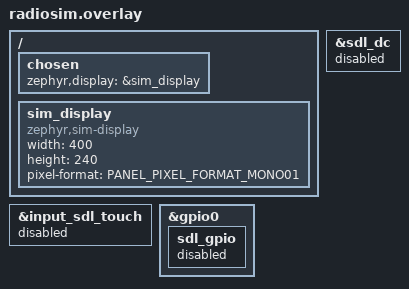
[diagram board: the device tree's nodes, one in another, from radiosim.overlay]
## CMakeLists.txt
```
# SPDX-License-Identifier: GPL-3.0-only

cmake_minimum_required(VERSION 3.20.0)

# The controller board itself: firmware/boards/others/alturia_controller.
list(APPEND BOARD_ROOT ${CMAKE_CURRENT_SOURCE_DIR}/..)

find_package(Zephyr REQUIRED HINTS $ENV{ZEPHYR_BASE})
project(launch_controller)

# Headers LVGL itself includes (1-bit blend fix, see prj.conf)
zephyr_include_directories(src/lvgl)

target_sources(app PRIVATE
	src/main.c
	src/controller.c
	src/pads.c
	src/game.c
	src/ui.c
	src/lvgl/i1_blend_fix.c
	src/ui/widgets.c
	src/ui/list.c
	src/ui/armed.c
	src/ui/launch.c
	src/ui/menu.c
	src/ui/pads.c
	src/ui/sats.c
	src/ui/diag.c
	src/ui/game.c
	src/ui/dialogs.c
	src/inputs.c
	src/power.c
	src/battery.c
	src/shell_cmds.c
	src/link_lsec.c
	src/ignlog.c
	src/ui/ignlog.c
	src/fonts/ui_font_18.c
	src/fonts/ui_font_20.c
	src/fonts/ui_font_28.c
	src/logo/ui_logo.c
)
# The views in src/ui include the app's headers from src
target_include_directories(app PRIVATE src)

# The controller's end of the secure link (../common/link). The satellite
# simulator stands in for the LoRa radio and the satellites; without it the
# link runs over the radio.
set(LSEC_LINK ctrl)
if(NOT CONFIG_APP_SAT_SIM)
	set(LSEC_RADIO ON)
endif()
include(${CMAKE_CURRENT_SOURCE_DIR}/../common/link/link_sec.cmake)

# Command and status payloads, shared with the satellite.
target_include_directories(app PRIVATE ../common/wire)
target_sources(app PRIVATE ../common/wire/sat_wire.c)

# Ignition log records, and their mcumgr group, shared with the satellite.
include(${CMAKE_CURRENT_SOURCE_DIR}/../common/ignlog/ignlog.cmake)

# Buzzer tunes, shared with the satellite.
target_include_directories(app PRIVATE ../common/chime)
target_sources(app PRIVATE ../common/chime/chime.c)

target_sources_ifdef(CONFIG_APP_SAT_SIM app PRIVATE src/sat_sim.c)
target_sources_ifdef(CONFIG_PM app PRIVATE src/sleep.c)

# A node of the radio network simulator (radiosim.conf, radiosim.overlay):
# the screen and the controls live in the simulator's web UI.
if(LSEC_RADIO_SIM)
	target_sources(app PRIVATE src/sim_display.c src/sim_panel.c)
endif()

# Firmware updates: refuse while armed, confirm a new image once up.
include(${CMAKE_CURRENT_SOURCE_DIR}/../common/mgmt/dfu_guard.cmake)
```

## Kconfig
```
mainmenu "Launch controller UI"

config APP_SAT_SIM
	bool "Simulated satellites and LoRa link"
	default y
	help
	  Replace the LoRa link with an in-process satellite simulator.
	  Fault injection is available through the "sat" shell command.

config APP_PREARM_CONTINUITY
	bool "Satellites report continuity while disarmed"
	default y
	help
	  The satellites' continuity readings are real before arming, so the
	  main list shows them. Without it the list shows "?" until the
	  pads are armed, and continuity is only judged from the armed
	  readings. The satellite firmware measures through V_TEST while
	  disarmed, one output every 0.65 s or so.

config APP_ARMED_BEEP
	bool "Click every 2 s while armed"
	default y
	help
	  The buzzer clicks every 2 s while pads are armed, so nobody near
	  the controller can miss it. Arming, disarming, a launch, a fault
	  and a refused button have their tunes either way.

config APP_POLL_PERIOD_MS
	int "Heartbeat poll period in milliseconds"
	default 1200
	help
	  How often the controller polls its satellites when it has nothing
	  new to tell them. Keep it well below LINK_SAT_SAFE_TIMEOUT_MS: a
	  satellite goes SAFE after that long without a poll.

config APP_CMD_RETRY_MS
	int "Command retry period in milliseconds"
	default 300
	help
	  While a command (ARM, DISARM, FIRE, a valve change) has not been
	  acknowledged by the satellite's status, the controller polls this
	  often (plus up to 100 ms of jitter) instead of the heartbeat period.

config APP_ARM_TIMEOUT_S
	int "Arm timeout in seconds"
	default 60
	help
	  Operator inactivity after which the controller disarms. FILL and
	  VENT restart it, and it is paused while a hybrid pad is filling.

config APP_FIRE_HOLD_MS
	int "Fire button hold time in milliseconds"
	default 1000
	help
	  The fire control must be held continuously for this long
	  before the fire command is sent.

config APP_IGNLOG_CACHE
	int "Ignition log records cached"
	default 8
	help
	  Records downloaded from the satellites' ignition logs that the
	  controller keeps, for its diagnostics view and for the browser
	  tool over mcumgr; the least recently used goes first. Each takes
	  32 + 2 * APP_IGNLOG_MAX_SAMPLES bytes of DRAM, which is nearly
	  full on the ESP32-S3 (the PSRAM is not enabled): 8 hold one
	  satellite's whole log in some 17 KB.

config APP_IGNLOG_MAX_SAMPLES
	int "Samples per ignition log record"
	default 1024
	help
	  The largest record the controller accepts; at least the
	  satellite's SAT_IGNLOG_MAX_SAMPLES.

rsource "../common/link/Kconfig"

source "Kconfig.zephyr"
```

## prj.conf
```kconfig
CONFIG_MAIN_STACK_SIZE=8192

CONFIG_LOG=y
CONFIG_SHELL=y

CONFIG_DISPLAY=y
CONFIG_DISPLAY_LOG_LEVEL_ERR=y
CONFIG_INPUT=y
# No touch: all input comes from physical controls
CONFIG_LV_Z_POINTER_FROM_CHOSEN_TOUCH=n
CONFIG_GPIO=y

CONFIG_LVGL=y
CONFIG_LV_Z_MEM_POOL_SIZE=196608
CONFIG_LV_Z_SHELL=y
CONFIG_LV_USE_LOG=y
# 1-bit Sharp Memory LCD class panel
CONFIG_LV_COLOR_DEPTH_1=y
# Fix inverted (white on black) text in 1-bit rendering, see src/lvgl/i1_blend_fix.h
CONFIG_LV_DRAW_SW_ASM_CUSTOM=y
CONFIG_LV_DRAW_SW_ASM_CUSTOM_INCLUDE="i1_blend_fix.h"
# UI fonts are generated, see src/fonts/gen.sh; this is only LVGL's default
CONFIG_LV_FONT_MONTSERRAT_14=y
CONFIG_LV_FONT_DEFAULT_MONTSERRAT_14=y
# Keep hyphenated words like E-STOP together when wrapping
CONFIG_LV_TXT_BREAK_CHARS=" ,.;:_)}"
CONFIG_LV_USE_THEME_DEFAULT=y
CONFIG_SHELL_LOG_BACKEND=n

# Persistent configuration (pad labels) on the storage partition
CONFIG_FLASH=y
CONFIG_FLASH_MAP=y
CONFIG_ZMS=y
CONFIG_SETTINGS=y
CONFIG_SETTINGS_ZMS=y
CONFIG_SETTINGS_SHELL=y

# Secure LoRa link, see documentation/radio_link.md: ECDH P-256 pairing,
# HMAC/HKDF-SHA256, AES-128-CCM frames
CONFIG_PSA_CRYPTO=y
CONFIG_MBEDTLS_ENABLE_HEAP=y
CONFIG_MBEDTLS_HEAP_SIZE=8192
CONFIG_PSA_WANT_KEY_TYPE_AES=y
CONFIG_PSA_WANT_ALG_CCM=y
CONFIG_PSA_WANT_ALG_SHA_256=y
CONFIG_PSA_WANT_ALG_HMAC=y
CONFIG_PSA_WANT_ALG_HKDF=y
CONFIG_PSA_WANT_ALG_ECDH=y
CONFIG_PSA_WANT_ECC_SECP_R1_256=y
CONFIG_PSA_WANT_KEY_TYPE_ECC_KEY_PAIR_GENERATE=y
CONFIG_PSA_WANT_KEY_TYPE_ECC_PUBLIC_KEY=y
CONFIG_ENTROPY_GENERATOR=y

# Reply slots are timed to the millisecond; the ESP32 default of 100 ticks
# per second would round every wait to 10 ms.
CONFIG_SYS_CLOCK_TICKS_PER_SEC=10000
```

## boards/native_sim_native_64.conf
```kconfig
# LVGL objects hold pointers, so on 64-bit native_sim the UI needs much
# more of LVGL's pool than on the 32-bit controller (192 KB, prj.conf).
# Check the board's use with "lvgl stats memory" in its shell.
CONFIG_LV_Z_MEM_POOL_SIZE=393216

# The emulated panel is small; show it at double size
CONFIG_SDL_DISPLAY_ZOOM_PCT=200
```

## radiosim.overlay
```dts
/*
 * The controller as a node of the radio network simulator (tools/radiosim):
 * no SDL window, the screen goes to the simulator's web UI, and its keys
 * come back from there onto the same gpio0 pins the SDL keyboard drives
 * in boards/native_sim.overlay. Use together with radiosim.conf.
 */

#include <zephyr/dt-bindings/display/panel.h>

&sdl_dc {
	status = "disabled";
};

&input_sdl_touch {
	status = "disabled";
};

&gpio0 {
	sdl_gpio {
		status = "disabled";
	};
};

/ {
	chosen {
		/delete-property/ zephyr,touch;
		zephyr,display = &sim_display;
	};

	sim_display: sim_display {
		compatible = "zephyr,sim-display";
		width = <400>;
		height = <240>;
		pixel-format = <PANEL_PIXEL_FORMAT_MONO01>;
	};
};
```

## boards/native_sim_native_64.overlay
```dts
/* 64-bit native_sim uses the same setup; avoids needing 32-bit SDL2. */
#include "native_sim.overlay"
```

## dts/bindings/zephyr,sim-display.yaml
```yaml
# SPDX-License-Identifier: GPL-3.0-only

description: |
  Display that exists only in the radio network simulator's web UI
  (tools/radiosim). Frames go there over the simulated radio's socket,
  see src/sim_display.c.

compatible: "zephyr,sim-display"

include: display-controller.yaml

properties:
  pixel-format:
    type: int
    required: true
    description: Initial pixel format, 1-bit only.
    enum:
      - 2 # PANEL_PIXEL_FORMAT_MONO01
      - 4 # PANEL_PIXEL_FORMAT_MONO10
```

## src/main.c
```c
/*
 * Launch controller UI test bench.
 *
 * LVGL runs in the main thread. The controller state machine is ticked
 * from an LVGL timer in the same thread, so UI and controller never race.
 */

#include <zephyr/device.h>
#include <zephyr/drivers/display.h>
#include <zephyr/kernel.h>
#include <zephyr/logging/log.h>
#include <lvgl.h>

#include "chime.h"
#include "controller.h"
#include "dfu_guard.h"
#include "link.h"
#include "pads.h"
#include "ui.h"

LOG_MODULE_REGISTER(app, LOG_LEVEL_INF);

#define CTRL_PERIOD_MS 50

/* After this long with the UI running, a newly updated image is kept. */
#define DFU_CONFIRM_MS 10000

/* mcumgr uploads and resets (common/mgmt/dfu_guard.c): only while SAFE. */
bool app_dfu_allowed(void)
{
	return ctrl_view()->state == CTRL_SAFE;
}

static void dfu_confirm_cb(lv_timer_t *timer)
{
	ARG_UNUSED(timer);
	dfu_image_ok();
}

static void ctrl_timer_cb(lv_timer_t *timer)
{
	ARG_UNUSED(timer);
	ctrl_tick();
	ui_refresh();
}

int main(void)
{
	const struct device *display = DEVICE_DT_GET(DT_CHOSEN(zephyr_display));

	if (!device_is_ready(display)) {
		LOG_ERR("display not ready");
		chime_error();
		dfu_image_bad();
		return 0;
	}

	/* The splash first, while the rest starts up */
	ui_init();
	lv_timer_handler();
	display_blanking_off(display);

	(void)pads_init();
	/* After pads_init(), which brings up the settings subsystem */
	if (link_init()) {
		LOG_ERR("secure link failed to start");
		chime_error();
		dfu_image_bad();
	} else {
		chime_startup();
	}
	lv_timer_create(ctrl_timer_cb, CTRL_PERIOD_MS, NULL);
	lv_timer_set_repeat_count(lv_timer_create(dfu_confirm_cb, DFU_CONFIRM_MS, NULL), 1);

	LOG_INF("launch controller UI running");

	/*
	 * Sleep until LVGL's next timer: the controller tick, or a redraw.
	 * Requests posted in between wait for the tick anyway, so waking more
	 * often would only cost battery.
	 */
	while (true) {
		uint32_t sleep_ms = lv_timer_handler();

		k_msleep(MIN(sleep_ms, CTRL_PERIOD_MS));
	}
	return 0;
}
```

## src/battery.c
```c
/* SPDX-License-Identifier: GPL-3.0-only */

#include <errno.h>

#include <zephyr/device.h>
#include <zephyr/drivers/charger.h>
#include <zephyr/drivers/fuel_gauge.h>
#include <zephyr/drivers/gpio.h>
#include <zephyr/kernel.h>
#include <zephyr/logging/log.h>
#include <zephyr/pm/policy.h>

#include "battery.h"

LOG_MODULE_REGISTER(battery, LOG_LEVEL_INF);

#define POLL_MS 2000

#define GAUGE_NODE   DT_ALIAS(fuel_gauge0)
#define CHARGER_NODE DT_ALIAS(charger0)
#define USER_NODE    DT_PATH(zephyr_user)

#define HAVE_GAUGE   (IS_ENABLED(CONFIG_FUEL_GAUGE) && DT_NODE_HAS_STATUS_OKAY(GAUGE_NODE))
#define HAVE_CHARGER (IS_ENABLED(CONFIG_CHARGER) && DT_NODE_HAS_STATUS_OKAY(CHARGER_NODE))

static K_MUTEX_DEFINE(lock);
static struct battery_info info = {.pgood = -1};

#if DT_NODE_HAS_PROP(USER_NODE, usb_pgood_gpios)
static const struct gpio_dt_spec pgood = GPIO_DT_SPEC_GET(USER_NODE, usb_pgood_gpios);
#endif

#if HAVE_GAUGE
static void read_gauge(struct battery_info *b)
{
	const struct device *dev = DEVICE_DT_GET(GAUGE_NODE);
	fuel_gauge_prop_t props[] = {
		FUEL_GAUGE_RELATIVE_STATE_OF_CHARGE_PCT,
		FUEL_GAUGE_VOLTAGE_UV,
		FUEL_GAUGE_RUNTIME_TO_EMPTY_MINS,
		FUEL_GAUGE_RUNTIME_TO_FULL_MINS,
	};
	union fuel_gauge_prop_val vals[ARRAY_SIZE(props)];

	b->gauge = device_is_ready(dev) &&
		   fuel_gauge_get_props(dev, props, vals, ARRAY_SIZE(props)) == 0;
	if (!b->gauge) {
		return;
	}
	b->soc_pct = MIN(vals[0].relative_state_of_charge_pct, 100);
	b->voltage_mv = vals[1].voltage_uv / 1000;
	b->to_empty_min = vals[2].runtime_to_empty_mins;
	b->to_full_min = vals[3].runtime_to_full_mins;
}
#endif

#if HAVE_CHARGER
static uint32_t charger_u32(const struct device *dev, charger_prop_t prop, bool *ok)
{
	union charger_propval val;

	if (charger_get_prop(dev, prop, &val)) {
		*ok = false;
		return 0;
	}
	/* Every property read here is a 32-bit current or voltage */
	return val.const_charge_current_ua;
}

static void read_charger(struct battery_info *b)
{
	const struct device *dev = DEVICE_DT_GET(CHARGER_NODE);
	union charger_propval val;
	bool ok = device_is_ready(dev);

	if (!ok) {
		b->charger = false;
		return;
	}
	ok &= charger_get_prop(dev, CHARGER_PROP_ONLINE, &val) == 0;
	b->online = val.online != CHARGER_ONLINE_OFFLINE;
	ok &= charger_get_prop(dev, CHARGER_PROP_STATUS, &val) == 0;
	b->status = val.status;
	ok &= charger_get_prop(dev, CHARGER_PROP_HEALTH, &val) == 0;
	b->health = val.health;

	b->ichg_ma = charger_u32(dev, CHARGER_PROP_CONSTANT_CHARGE_CURRENT_UA, &ok) / 1000;
	b->vreg_mv = charger_u32(dev, CHARGER_PROP_CONSTANT_CHARGE_VOLTAGE_UV, &ok) / 1000;
	b->iinlim_ma = charger_u32(dev, CHARGER_PROP_INPUT_REGULATION_CURRENT_UA, &ok) / 1000;
	b->vindpm_mv = charger_u32(dev, CHARGER_PROP_INPUT_REGULATION_VOLTAGE_UV, &ok) / 1000;
	b->iprechg_ma = charger_u32(dev, CHARGER_PROP_PRECHARGE_CURRENT_UA, &ok) / 1000;
	b->iterm_ma = charger_u32(dev, CHARGER_PROP_CHARGE_TERM_CURRENT_UA, &ok) / 1000;
	b->charger = ok;
}
#endif

static void poll(struct k_work *work);
static K_WORK_DELAYABLE_DEFINE(poll_work, poll);

static void poll(struct k_work *work)
{
	struct battery_info b;

	ARG_UNUSED(work);

	k_mutex_lock(&lock, K_FOREVER);
	b = info;
	k_mutex_unlock(&lock);

	/* The I2C driver sleeps on its interrupt; light sleep would stop its clock */
	pm_policy_state_all_lock_get();
#if HAVE_GAUGE
	read_gauge(&b);
#endif
#if HAVE_CHARGER
	read_charger(&b);
#endif
	pm_policy_state_all_lock_put();
#if DT_NODE_HAS_PROP(USER_NODE, usb_pgood_gpios)
	b.pgood = gpio_pin_get_dt(&pgood);
	b.pgood = b.pgood < 0 ? -1 : b.pgood;
#endif

	k_mutex_lock(&lock, K_FOREVER);
	info = b;
	k_mutex_unlock(&lock);

	k_work_reschedule(&poll_work, K_MSEC(POLL_MS));
}

static int battery_init(void)
{
#if DT_NODE_HAS_PROP(USER_NODE, usb_pgood_gpios)
	if (gpio_is_ready_dt(&pgood)) {
		(void)gpio_pin_configure_dt(&pgood, GPIO_INPUT);
	}
#endif
	k_work_reschedule(&poll_work, K_NO_WAIT);
	return 0;
}

SYS_INIT(battery_init, APPLICATION, 1);

void battery_get(struct battery_info *out)
{
	k_mutex_lock(&lock, K_FOREVER);
	*out = info;
	k_mutex_unlock(&lock);
}

bool battery_charging(const struct battery_info *b)
{
	return b->charger && b->status == CHARGER_STATUS_CHARGING;
}

int battery_fake(uint8_t soc_pct, bool charging)
{
	if (HAVE_GAUGE) {
		return -EBUSY;
	}
	k_mutex_lock(&lock, K_FOREVER);
	info.gauge = true;
	info.soc_pct = MIN(soc_pct, 100);
	info.voltage_mv = 3300 + 9 * info.soc_pct;
	info.charger = true;
	info.online = charging;
	info.status = charging ? CHARGER_STATUS_CHARGING : CHARGER_STATUS_DISCHARGING;
	info.health = CHARGER_HEALTH_GOOD;
	k_mutex_unlock(&lock);
	return 0;
}

const char *battery_status_text(enum charger_status status)
{
	switch (status) {
	case CHARGER_STATUS_CHARGING:
		return "charging";
	case CHARGER_STATUS_DISCHARGING:
		return "discharging";
	case CHARGER_STATUS_NOT_CHARGING:
		return "not charging";
	case CHARGER_STATUS_FULL:
		return "full";
	default:
		return "unknown";
	}
}

const char *battery_health_text(enum charger_health health)
{
	switch (health) {
	case CHARGER_HEALTH_GOOD:
		return "good";
	case CHARGER_HEALTH_OVERHEAT:
		return "overheat";
	case CHARGER_HEALTH_OVERVOLTAGE:
		return "overvoltage";
	case CHARGER_HEALTH_UNSPEC_FAILURE:
		return "input fault";
	case CHARGER_HEALTH_COLD:
		return "too cold";
	case CHARGER_HEALTH_WATCHDOG_TIMER_EXPIRE:
		return "watchdog";
	case CHARGER_HEALTH_SAFETY_TIMER_EXPIRE:
		return "timer expired";
	case CHARGER_HEALTH_HOT:
		return "too hot";
	default:
		return "unknown";
	}
}
```

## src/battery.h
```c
/*
 * The controller's own battery: MAX17048 fuel gauge, BQ24296M charger and
 * the charger's power-good line, read every couple of seconds.
 */

#ifndef BATTERY_H_
#define BATTERY_H_

#include <stdbool.h>
#include <stdint.h>

#include <zephyr/drivers/charger.h>

struct battery_info {
	/* Fuel gauge */
	bool gauge;               /* the readings below are valid */
	uint8_t soc_pct;
	uint32_t voltage_mv;
	uint32_t to_empty_min;    /* 0: not discharging */
	uint32_t to_full_min;     /* 0: not charging */

	/* Charger */
	bool charger;             /* the readings below are valid */
	bool online;              /* input power present */
	enum charger_status status;
	enum charger_health health;
	uint32_t ichg_ma;         /* fast charge current */
	uint32_t vreg_mv;         /* charge voltage */
	uint32_t iinlim_ma;       /* input current limit */
	uint32_t vindpm_mv;       /* input voltage limit */
	uint32_t iprechg_ma;
	uint32_t iterm_ma;

	int pgood;                /* USB_PGOOD: 1 good, 0 not, -1 no such line */
};

void battery_get(struct battery_info *out);

/* Charging, as the charger reports it */
bool battery_charging(const struct battery_info *b);

const char *battery_status_text(enum charger_status status);
const char *battery_health_text(enum charger_health health);

/*
 * Stand-in readings for boards without a fuel gauge (native_sim), to try
 * the UI from the shell.
 */
int battery_fake(uint8_t soc_pct, bool charging);

#endif /* BATTERY_H_ */
```

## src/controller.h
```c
/*
 * Controller state machine. Owns every arm/fire/valve decision; the UI
 * only reads ctrl_view(). User intent arrives through ctrl_post(), from
 * the button input callback or the shell.
 * ctrl_tick() and ctrl_view() run in the LVGL thread.
 *
 * Operators select pads, not channels. The main list shows the pads of
 * every paired satellite, grouped by satellite in channel order; up and
 * down move over them, left and right jump to the previous and next
 * satellite, OK ticks a pad and BACK clears the ticks. ARM arms the ticked
 * pads, or the pad under the cursor if none is ticked, on every satellite
 * that hosts one of them. FIRE launches them all at once. On hybrid pads,
 * FILL and VENT toggle the valves while armed; either one, and LAUNCH,
 * stops a running fill.
 *
 * The controls are a D-pad (up, down, left, right, OK), BACK, ARM, FIRE,
 * FILL, VENT and the power button. BACK disarms, acknowledges a fault and
 * backs out of a screen.
 *
 * In SAFE, holding OK opens the menu:
 *  - Edit pad: the setup screen of the pad under the cursor.
 *  - Pads: every channel of every satellite and the pad using it; OK
 *    sets that pad up, or on a free channel sets up a new rocket pad.
 *  - Satellites: pairing and forgetting.
 *  - Messages: the last events, newest first.
 *  - Diagnostics, a menu of its own: the button test, which shows every
 *    button press instead of acting on it (holding BACK leaves), the
 *    battery, the ignition log (the current of a satellite's last fire
 *    pulses, downloaded over LoRa, see ignlog.h), and Stacker, a
 *    falling-block game (game.h) that takes the D-pad for itself until
 *    BACK pauses it.
 *  - Power off.
 * While any of these is open, the D-pad acts on it, BACK backs out one
 * level, and ARM, FILL and VENT are refused. The power button asks to
 * switch off from anywhere in SAFE.
 */

#ifndef CONTROLLER_H_
#define CONTROLLER_H_

#include <stdbool.h>
#include <stdint.h>

#include "link.h"
#include "pads.h"

enum ctrl_state {
	CTRL_SAFE,
	CTRL_ARMING,
	CTRL_ARMED,
	CTRL_FIRING,
};

enum msg_level {
	MSG_INFO,   /* normal progress */
	MSG_WARN,   /* request refused or degraded, nothing unsafe happened */
	MSG_FAULT,  /* something went wrong during arm/fire, demands attention */
};

/* Commanded valve state of an armed hybrid pad */
enum hybrid_op {
	HYB_CLOSED,   /* fill closed, vent closed */
	HYB_FILLING,  /* fill open, vent closed */
	HYB_VENTING,  /* fill closed, vent open */
};

struct sat_view {
	uint64_t uid;   /* the paired satellite, 0 if none */
	bool joined;    /* secure session up */
	bool have_status;
	bool link_ok;   /* status received within the link timeout */
	/*
	 * Connected as far as the operator is told. Drops with link_ok, but
	 * only returns once the link has been stable for a while, so the
	 * state does not flicker at the edge of the radio range.
	 */
	bool visible;
	int64_t ok_since;
	int64_t rx_time;   /* uptime of the last status, -1 if none yet */
	struct sat_status st;
};

struct pad_view {
	/* Channel with a continuity problem, as text ("IGN OPEN"), or NULL */
	const char *problem;
	/*
	 * Whether it stops a launch: an open output does, a shorted one only
	 * warns. Firing into a short is up to the operator; the TPS1HB08
	 * current limit and thermal shutdown protect the channel.
	 */
	bool problem_blocks;
	enum hybrid_op op;
	int64_t fill_start;
};

/* Characters offered by the label editor, in turning order */
#define LABEL_CHARSET " ABCDEFGHIJKLMNOPQRSTUVWXYZ0123456789-./#"

enum setup_field {
	FIELD_LABEL,
	FIELD_TYPE,
	FIELD_SAT,
	FIELD_IGN,
	FIELD_FILL,
	FIELD_VENT,
	FIELD_COUNT,
};

enum setup_mode {
	SETUP_FIELDS,  /* up/down: field, left/right: its value */
	SETUP_LABEL,   /* up/down: character, left/right: position */
};

/* Pad setup screen */
struct pad_setup {
	bool active;
	enum setup_mode mode;
	int pad;
	int field;
	int pos;                          /* label character being edited */
	char label[PAD_LABEL_MAX + 1];    /* being edited, space padded; BACK drops it */
	struct pad_cfg cfg;               /* draft */
	bool is_new;                      /* the pad was OFF: a new one */
	const char *error;                /* why the draft cannot be saved */
};

/* A list with a cursor: a menu, or the pad list */
struct menu_view {
	bool active;
	int cursor;
};

/* Menu entries, top to bottom */
enum settings_entry {
	SETTINGS_EDIT,
	SETTINGS_PADS,
	SETTINGS_SATS,
	SETTINGS_MSGS,
	SETTINGS_DIAG,
	SETTINGS_OFF,
	SETTINGS_COUNT,
};

/* Diagnostics menu entries, and the screen they open */
enum diag_entry {
	DIAG_BUTTONS,
	DIAG_BATTERY,
	DIAG_IGNLOG,
	DIAG_GAME,
	DIAG_COUNT,
	DIAG_NONE = -1,
};

/*
 * Ignition log, from the diagnostics menu: pick a satellite, then one of
 * its records (newest first), then its current over time.
 */
enum ignlog_page {
	IGNLOG_PAGE_SATS,
	IGNLOG_PAGE_LIST,
	IGNLOG_PAGE_CHART,
};

/* The chart's zoomed-in window: where an igniter burns through */
#define IGNLOG_ZOOM_MS 50

struct ignlog_view {
	enum ignlog_page page;
	int sat;          /* the satellite, and the cursor on the first page */
	int cursor;       /* record list row, 0 = newest */
	uint32_t seq;     /* the record on the chart */
	bool zoom;        /* chart: the first IGNLOG_ZOOM_MS only */
};

/* Satellites screen, opened from the settings screen */
struct sats_view {
	bool active;
	int cursor;
};

enum pair_phase {
	PAIR_SCAN,       /* listing satellites in pairing mode */
	PAIR_WAIT,       /* key exchange running */
	PAIR_COMPARE,    /* pattern shown, waiting for the operator */
	PAIR_CONFIRMED,  /* operator confirmed, waiting for the satellite's */
};

#define PAIR_MAX_FOUND 4

/*
 * Pairing one satellite slot, see documentation/radio_link.md. The operator
 * compares the pattern with the satellite's channel LEDs and confirms on
 * both devices.
 */
struct pair_view {
	bool active;
	enum pair_phase phase;
	int sat;
	int found;
	int cursor;
	uint64_t uid[PAIR_MAX_FOUND];
	int16_t rssi_dbm[PAIR_MAX_FOUND];
	uint8_t sas[LSEC_SAS_FRAMES];
};

/* Rows of the armed continuity table visible at once; up and down scroll */
#define ARMED_TABLE_ROWS 5

/* Messages visible at once on the messages screen */
#define MESSAGES_ROWS 8

struct ctrl_view {
	enum ctrl_state state;
	struct sat_view sat[NUM_SATS];
	struct pad_view pad[NUM_PADS];
	uint64_t selected;        /* ticked pads, BIT64(pad); while armed, the armed ones */
	/* What ARM would arm now: the ticked pads, else the one under the cursor */
	uint64_t arm_set;
	int cursor;               /* pad under the list cursor, -1 if none is listed */
	int table_scroll;         /* first visible row of the armed table */
	struct menu_view settings;    /* the menu, opened by holding OK */
	/* Channels of all satellites, from the menu; cursor: see ctrl_pads_sats() */
	struct menu_view pad_list;
	struct pad_setup setup;       /* from the menu or the channel list */
	struct menu_view messages;    /* from the menu; cursor: newest shown */
	struct sats_view sats;        /* from the settings menu */
	struct pair_view pair;        /* opened from the satellites screen */
	struct menu_view diag_menu;   /* from the settings menu */
	int diag;                     /* open diagnostics screen, DIAG_NONE if none */
	struct ignlog_view ignlog;    /* diag == DIAG_IGNLOG */
	bool power_confirm;       /* asking whether to switch off */
	bool powering_off;        /* switched off, waiting for the power to go */
	/* Why arming is currently not possible, NULL if it is */
	const char *arm_block;
	/* Why launching is currently not possible while armed, NULL if it is */
	const char *launch_block;
	int32_t arm_remaining_ms;
	bool arm_timer_paused;    /* while filling */
	int32_t fire_hold_ms;
	char message[80];
	enum msg_level message_level;
	int64_t message_time;
	bool fault_active;        /* the last fault still needs a BACK press */
	uint8_t channel_util;     /* % busy, every network counted */
	uint8_t other_nets;       /* other controllers' networks heard */
	bool channel_crowded;     /* commands may take several tries */
};

void ctrl_tick(void);
const struct ctrl_view *ctrl_view(void);
const char *ctrl_state_name(enum ctrl_state state);

/* In the main list: enabled, on a paired satellite */
bool ctrl_pad_listed(int p);

/*
 * The listed pads in the main list's order: by satellite, then by
 * igniter channel. Returns how many.
 */
int ctrl_list_order(int order[NUM_PADS]);

/*
 * The satellites on the Pads screen: paired ones and any that pads are
 * set up on. Returns how many. Its cursor is index * NUM_CHANNELS + channel.
 */
int ctrl_pads_sats(int sats[NUM_SATS]);

/* The enabled pad that uses a satellite channel, -1 if it is free */
int ctrl_channel_pad(int sat, int ch);

/* The last messages, newest first */
#define CTRL_EVENTS 16

struct ctrl_event {
	char text[80];
	enum msg_level level;
	int64_t time;
};

/* The age-th most recent message (0 = the latest), NULL past the oldest */
const struct ctrl_event *ctrl_event(int age);

enum ctrl_req_type {
	CTRL_REQ_TOGGLE_PAD,  /* arg: pad */
	CTRL_REQ_CURSOR,      /* up/down, arg: rows to move, negative is up */
	CTRL_REQ_ADJUST,      /* left/right, arg: steps, negative is left */
	CTRL_REQ_SELECT,      /* OK: toggle the pad under the cursor */
	CTRL_REQ_EDIT,        /* OK held: settings, or save in pad setup */
	CTRL_REQ_ARM,
	CTRL_REQ_BACK,        /* disarm, acknowledge, back out */
	CTRL_REQ_BACK_LONG,   /* BACK held: leaves the button test */
	CTRL_REQ_FILL,
	CTRL_REQ_VENT,
	CTRL_REQ_POWER,       /* power button: ask to switch off */
};

/* Thread-safe; the request is executed in the next ctrl_tick(). */
void ctrl_post(enum ctrl_req_type type, int arg);

#endif /* CONTROLLER_H_ */
```

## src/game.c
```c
/* SPDX-License-Identifier: GPL-3.0-only */

/*
 * Stacker, see game.h. Runs in the LVGL thread, one step per controller
 * tick (50 ms), so every time below is a multiple of that in practice.
 *
 * Button presses are taken from the press counters of inputs_diag()
 * rather than from the controller's request queue: a counter does not
 * miss a tap shorter than a tick, and it has no auto-repeat, so holding
 * up turns a shape once. Held buttons (left, right, down) are read as
 * levels.
 */

#include <string.h>

#include <zephyr/kernel.h>
#include <zephyr/sys/util.h>

#include "game.h"
#include "inputs.h"

/* Held left or right: first repeat after this, then one column per tick */
#define REPEAT_DELAY_MS 170
#define REPEAT_MS       50
/* Held down: one row per tick */
#define SOFT_DROP_MS    50
/* A shape that touches down can still be moved for this long... */
#define LOCK_MS         500
/* ...but moving it restarts that only so often */
#define LOCK_RESETS     15
/* After the game ends, OK starts a new one only after this */
#define OVER_GUARD_MS   800
/* A longer gap between ticks: the screen was left, the game paused */
#define PAUSE_GAP_MS    300

/* Rows per level, and the time a shape takes to fall one row */
#define LINES_PER_LEVEL 10
static const uint16_t fall_ms[] = {
	800, 680, 580, 490, 420, 355, 300, 255, 220, 185, 160, 135, 115, 100, 85, 70, 60, 50,
};

/* Points for 1, 2, 3 and 4 rows at once, times (level + 1) */
static const uint16_t row_points[] = {0, 100, 300, 500, 800};

/* The seven shapes: four blocks each in an n x n box, x right, y down */
struct shape {
	uint8_t n;
	int8_t spawn_y;   /* so that the top block starts in row 0 */
	uint8_t cell[4][2];
};

static const struct shape shapes[] = {
	{4, -1, {{0, 1}, {1, 1}, {2, 1}, {3, 1}}},   /* I */
	{2, 0, {{0, 0}, {1, 0}, {0, 1}, {1, 1}}},    /* O */
	{3, 0, {{1, 0}, {0, 1}, {1, 1}, {2, 1}}},    /* T */
	{3, 0, {{1, 0}, {2, 0}, {0, 1}, {1, 1}}},    /* S */
	{3, 0, {{0, 0}, {1, 0}, {1, 1}, {2, 1}}},    /* Z */
	{3, 0, {{0, 0}, {0, 1}, {1, 1}, {2, 1}}},    /* J */
	{3, 0, {{2, 0}, {0, 1}, {1, 1}, {2, 1}}},    /* L */
};

#define NUM_SHAPES ARRAY_SIZE(shapes)

/* Turning against a wall or the floor: the offsets tried, in order */
static const int8_t kicks[][2] = {{0, 0}, {1, 0}, {-1, 0}, {0, -1}, {2, 0}, {-2, 0}};

struct piece {
	int shape;
	int rot;   /* quarter turns clockwise */
	int x;     /* box position in the well */
	int y;
};

static struct game_view gv;
static struct piece cur;
static bool started;
static int64_t last_tick;

static uint32_t rng;
static uint8_t bag[NUM_SHAPES];
static int bag_left;
static int next_shape;

static int64_t next_fall;
static int64_t lock_at;       /* -1 while not touching down */
static int lock_resets;
static int64_t over_since;

static uint32_t seen[BTN_COUNT];   /* press counters at the last tick */
static int move_dir;               /* -1 left, 1 right, 0 none held */
static int64_t next_repeat;
static int64_t next_soft;

static uint32_t xorshift(void)
{
	rng ^= rng << 13;
	rng ^= rng >> 17;
	rng ^= rng << 5;
	return rng;
}

/* Every shape once per seven, in a random order */
static int draw_shape(void)
{
	if (bag_left == 0) {
		for (int i = 0; i < NUM_SHAPES; i++) {
			bag[i] = i;
		}
		for (int i = NUM_SHAPES - 1; i > 0; i--) {
			int j = xorshift() % (i + 1);
			uint8_t t = bag[i];

			bag[i] = bag[j];
			bag[j] = t;
		}
		bag_left = NUM_SHAPES;
	}
	return bag[--bag_left];
}

/* Block i of a shape turned rot times, in its box */
static void cell_of(int shape, int rot, int i, int *cx, int *cy)
{
	const struct shape *s = &shapes[shape];
	int x = s->cell[i][0];
	int y = s->cell[i][1];

	for (int r = 0; r < (rot & 3); r++) {
		int t = x;

		x = s->n - 1 - y;
		y = t;
	}
	*cx = x;
	*cy = y;
}

/* Room for the piece: inside the walls, above the floor, on free cells */
static bool fits(const struct piece *p)
{
	for (int i = 0; i < 4; i++) {
		int cx, cy;

		cell_of(p->shape, p->rot, i, &cx, &cy);
		cx += p->x;
		cy += p->y;
		if (cx < 0 || cx >= GAME_COLS || cy >= GAME_ROWS) {
			return false;
		}
		if (cy >= 0 && (gv.well[cy] & BIT(cx))) {
			return false;
		}
	}
	return true;
}

static void stamp(uint16_t rows[GAME_ROWS], const struct piece *p)
{
	for (int i = 0; i < 4; i++) {
		int cx, cy;

		cell_of(p->shape, p->rot, i, &cx, &cy);
		cy += p->y;
		if (cy >= 0 && cy < GAME_ROWS) {
			rows[cy] |= BIT(cx + p->x);
		}
	}
}

static uint32_t fall_period(void)
{
	return fall_ms[MIN(gv.level, ARRAY_SIZE(fall_ms) - 1)];
}

/* Next shape in at the top; no room for it ends the game */
static void spawn(int64_t now)
{
	const struct shape *s = &shapes[next_shape];

	cur = (struct piece){
		.shape = next_shape,
		.x = (GAME_COLS - s->n) / 2,
		.y = s->spawn_y,
	};
	next_shape = draw_shape();
	next_fall = now + fall_period();
	lock_at = -1;
	lock_resets = 0;

	if (!fits(&cur)) {
		gv.phase = GAME_OVER;
		over_since = now;
	}
}

static void new_game(int64_t now)
{
	uint32_t best = gv.best;
	uint32_t version = gv.version;

	memset(&gv, 0, sizeof(gv));
	gv.best = best;
	gv.version = version + 1;
	rng ^= k_cycle_get_32();
	if (rng == 0) {
		rng = 1;
	}
	bag_left = 0;
	next_shape = draw_shape();
	spawn(now);
}

static bool on_floor(void)
{
	struct piece down = cur;

	down.y++;
	return !fits(&down);
}

/* A successful move or turn while touching down buys some time */
static void moved(int64_t now)
{
	if (lock_at >= 0 && lock_resets < LOCK_RESETS) {
		lock_resets++;
		lock_at = now + LOCK_MS;
	}
	if (lock_at >= 0 && !on_floor()) {
		lock_at = -1;   /* slid off an edge: falling again */
		next_fall = now + fall_period();
	}
}

static bool shift(int dx, int64_t now)
{
	struct piece p = cur;

	p.x += dx;
	if (!fits(&p)) {
		return false;
	}
	cur = p;
	moved(now);
	return true;
}

static void turn(int64_t now)
{
	ARRAY_FOR_EACH(kicks, k) {
		struct piece p = cur;

		p.rot = (cur.rot + 1) & 3;
		p.x += kicks[k][0];
		p.y += kicks[k][1];
		if (fits(&p)) {
			cur = p;
			moved(now);
			return;
		}
	}
}

/* Settle the piece, clear full rows, score them, bring the next shape */
static void lock(int64_t now)
{
	int cleared = 0;

	stamp(gv.well, &cur);

	/* Settled with a block above the top: no room left */
	for (int i = 0; i < 4; i++) {
		int cx, cy;

		cell_of(cur.shape, cur.rot, i, &cx, &cy);
		if (cur.y + cy < 0) {
			gv.phase = GAME_OVER;
			over_since = now;
			return;
		}
	}

	for (int r = GAME_ROWS - 1; r >= 0;) {
		if (gv.well[r] == BIT_MASK(GAME_COLS)) {
			memmove(&gv.well[1], &gv.well[0], r * sizeof(gv.well[0]));
			gv.well[0] = 0;
			cleared++;
		} else {
			r--;
		}
	}
	if (cleared) {
		gv.score += row_points[cleared] * (gv.level + 1);
		gv.lines += cleared;
		gv.level = gv.lines / LINES_PER_LEVEL;
	}
	spawn(now);
}

/* One row down; touching down starts the lock delay instead */
static bool fall(int64_t now)
{
	if (on_floor()) {
		if (lock_at < 0) {
			lock_at = now + LOCK_MS;
		}
		return false;
	}
	cur.y++;
	return true;
}

static void hard_drop(int64_t now)
{
	while (!on_floor()) {
		cur.y++;
		gv.score += 2;
	}
	lock(now);
}

/* The screen was away: shift every deadline by the time it was */
static void resume(int64_t gap)
{
	next_fall += gap;
	next_soft += gap;
	next_repeat += gap;
	if (lock_at >= 0) {
		lock_at += gap;
	}
	move_dir = 0;
}

/* Presses of a button since the last tick */
static uint32_t presses(const struct inputs_diag *d, enum button b)
{
	uint32_t n = d->count[b] - seen[b];

	seen[b] = d->count[b];
	return n;
}

static void play(const struct inputs_diag *d, int64_t now)
{
	bool left = d->pressed & BIT(BTN_LEFT);
	bool right = d->pressed & BIT(BTN_RIGHT);
	uint32_t n_left = presses(d, BTN_LEFT);
	uint32_t n_right = presses(d, BTN_RIGHT);
	uint32_t n_up = presses(d, BTN_UP);
	uint32_t n_ok = presses(d, BTN_OK);
	uint32_t n_down = presses(d, BTN_DOWN);

	/* Left and right: once per press, then repeating while held */
	for (uint32_t i = 0; i < n_left; i++) {
		shift(-1, now);
	}
	for (uint32_t i = 0; i < n_right; i++) {
		shift(1, now);
	}
	if (n_left || n_right) {
		/* The one pressed last wins while both are held */
		move_dir = n_right ? 1 : -1;
		next_repeat = now + REPEAT_DELAY_MS;
	}
	if ((move_dir < 0 && !left) || (move_dir > 0 && !right)) {
		move_dir = left ? -1 : right ? 1 : 0;
		next_repeat = now + REPEAT_DELAY_MS;
	}
	if (move_dir && now >= next_repeat) {
		shift(move_dir, now);
		next_repeat = now + REPEAT_MS;
	}

	for (uint32_t i = 0; i < n_up; i++) {
		turn(now);
	}
	if (n_ok) {
		hard_drop(now);
		return;
	}

	/* Down: a row per press, then faster while held; a point per row */
	for (uint32_t i = 0; i < n_down; i++) {
		if (fall(now)) {
			gv.score++;
			next_fall = now + fall_period();
		}
		next_soft = now + SOFT_DROP_MS;
	}
	if ((d->pressed & BIT(BTN_DOWN)) && now >= next_soft) {
		if (fall(now)) {
			gv.score++;
			next_fall = now + fall_period();
		}
		next_soft = now + SOFT_DROP_MS;
	}
	if (now >= next_fall) {
		fall(now);
		next_fall = now + fall_period();
	}
	if (lock_at >= 0) {
		if (!on_floor()) {
			lock_at = -1;
		} else if (now >= lock_at) {
			lock(now);
		}
	}
}

/* What the screen shows, from the state above */
static void build_view(void)
{
	struct game_view old = gv;
	struct piece ghost = cur;

	memset(gv.falling, 0, sizeof(gv.falling));
	memset(gv.ghost, 0, sizeof(gv.ghost));
	memset(gv.next, 0, sizeof(gv.next));

	if (gv.phase == GAME_PLAYING) {
		stamp(gv.falling, &cur);
		ghost.y++;
		while (fits(&ghost)) {
			ghost.y++;
		}
		ghost.y--;
		stamp(gv.ghost, &ghost);
	}
	/* Roughly centred in its 4 x 4 box */
	for (int i = 0; i < 4; i++) {
		int n = shapes[next_shape].n;
		int cx, cy;

		cell_of(next_shape, 0, i, &cx, &cy);
		gv.next[cy + (n == 4 ? 0 : 1)] |= BIT(cx + (n == 2 ? 1 : 0));
	}
	gv.best = MAX(gv.best, gv.score);

	old.version = gv.version;
	if (memcmp(&old, &gv, sizeof(gv)) != 0) {
		gv.version++;
	}
}

const struct game_view *game_tick(int64_t now)
{
	struct inputs_diag d;

	inputs_diag(&d);

	if (!started) {
		started = true;
		memcpy(seen, d.count, sizeof(seen));
		new_game(now);
	} else if (now - last_tick > PAUSE_GAP_MS) {
		/* Back on the screen: ignore what was pressed meanwhile */
		memcpy(seen, d.count, sizeof(seen));
		resume(now - last_tick);
	}
	last_tick = now;

	if (gv.phase == GAME_OVER) {
		if (presses(&d, BTN_OK) && now - over_since >= OVER_GUARD_MS) {
			new_game(now);
		}
		memcpy(seen, d.count, sizeof(seen));
	} else {
		play(&d, now);
	}

	build_view();
	return &gv;
}
```

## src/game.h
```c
/* SPDX-License-Identifier: GPL-3.0-only */

/*
 * Stacker: a falling-block game on the diagnostics menu, a gimmick that
 * doubles as a test of the D-pad and the panel.
 *
 * Seven shapes of four blocks fall into a well 10 wide and 20 deep. Left
 * and right move the falling one (held, they repeat), up turns it, down
 * drops it faster and OK drops it all the way. A full row disappears;
 * every ten rows the shapes fall faster. The game ends when a new shape
 * has no room.
 *
 * The game reads the buttons itself (inputs_diag()), so the controller
 * only has to keep its own hands off them while the screen is open.
 * Leaving the screen pauses the game, coming back resumes it.
 */

#ifndef GAME_H_
#define GAME_H_

#include <stdbool.h>
#include <stdint.h>

#define GAME_COLS 10
#define GAME_ROWS 20

enum game_phase {
	GAME_PLAYING,
	GAME_OVER,      /* OK starts a new game */
};

struct game_view {
	enum game_phase phase;
	/* Settled blocks and the falling shape, a bit per column, row 0 on top */
	uint16_t well[GAME_ROWS];
	uint16_t falling[GAME_ROWS];
	uint16_t ghost[GAME_ROWS];     /* where the falling shape would land */
	uint16_t next[4];              /* the next shape, in a 4x4 box */
	uint32_t score;
	uint32_t best;                 /* since power on */
	uint32_t lines;
	uint32_t level;
	uint32_t version;              /* changes whenever anything above does */
};

/* Advance the game to @p now (uptime, ms). Call every tick while shown. */
const struct game_view *game_tick(int64_t now);

#endif /* GAME_H_ */
```

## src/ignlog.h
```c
/* SPDX-License-Identifier: GPL-3.0-only */

/*
 * The satellites' ignition logs, downloaded over LoRa (ignlog.c): each
 * satellite's index, and a cache of the records asked for. The download
 * runs one log poll at a time, only while nothing is armed and no command
 * waits for its acknowledgement; see documentation/ignition_log.md. The
 * records are in the format of common/ignlog/ignlog_rec.h, byte for byte
 * as the satellite holds them, and are served again over mcumgr.
 *
 * Everything here runs on the LVGL thread (ctrl_tick() and the views),
 * except ignlog_rx() on the link thread and the mcumgr backend on the
 * mcumgr work queue.
 */

#ifndef CTRL_IGNLOG_H_
#define CTRL_IGNLOG_H_

#include <stdbool.h>
#include <stddef.h>
#include <stdint.h>

#include "ignlog_rec.h"

enum ignlog_job_state {
	IGNLOG_IDLE,
	IGNLOG_BUSY,
	IGNLOG_DONE,
	IGNLOG_FAILED,
};

struct ignlog_progress {
	enum ignlog_job_state state;
	int sat;             /* -1: no download yet */
	uint32_t seq;        /* the record being downloaded, 0 for the index */
	size_t done, total;  /* bytes of it */
	bool paused;         /* waiting for the link to be free of commands */
	const char *error;   /* IGNLOG_FAILED: why */
};

/* A log reply from satellite @p sat, from the link thread. */
void ignlog_rx(int sat, const uint8_t *buf, size_t len);

/*
 * Run the download, from ctrl_tick(). @p allowed while the controller is
 * SAFE and no command waits for its acknowledgement; otherwise no new log
 * poll goes out.
 */
void ignlog_tick(int64_t now, bool allowed);

/* Each replaces the download running. -ENOTCONN if @p sat is not joined. */
int ignlog_get_index(int sat);
int ignlog_get_record(int sat, uint32_t seq);
/* The index, then every record not yet held. */
int ignlog_get_all(int sat);
void ignlog_cancel(void);

void ignlog_progress(struct ignlog_progress *p);

/*
 * The last index of satellite @p sat, false if there is none. now_ms is
 * moved on to the satellite's uptime now; have marks the records held.
 */
bool ignlog_index(int sat, struct ignlog_store_view *v);

/*
 * A record held whole, or NULL. The pointer stays valid on the LVGL thread
 * until the next ignlog_tick().
 */
const uint8_t *ignlog_record(int sat, uint32_t seq, size_t *len);

#endif /* CTRL_IGNLOG_H_ */
```

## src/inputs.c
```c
#include <string.h>

#include <zephyr/device.h>
#include <zephyr/input/input.h>
#include <zephyr/kernel.h>
#include <zephyr/logging/log.h>
#include <zephyr/spinlock.h>
#include <zephyr/sys/atomic.h>

#include "controller.h"
#include "inputs.h"

LOG_MODULE_REGISTER(inputs, LOG_LEVEL_INF);

/* Levels, written from the input thread and read from the LVGL thread */
static atomic_t fire_held;

/* OK or BACK held this long is a long press */
#define LONG_PRESS_MS 600

static atomic_t ok_long_fired;

static void ok_long_press(struct k_work *work)
{
	ARG_UNUSED(work);
	atomic_set(&ok_long_fired, 1);
	ctrl_post(CTRL_REQ_EDIT, 0);
}

static K_WORK_DELAYABLE_DEFINE(ok_long_work, ok_long_press);

static void back_long_press(struct k_work *work)
{
	ARG_UNUSED(work);
	ctrl_post(CTRL_REQ_BACK_LONG, 0);
}

static K_WORK_DELAYABLE_DEFINE(back_long_work, back_long_press);

/* Up or down held: the cursor keeps moving, for long lists */
#define REPEAT_DELAY_MS  400
#define REPEAT_PERIOD_MS 120

static atomic_t repeat_dir;   /* -1 up, 1 down, 0 neither held */

static void repeat_step(struct k_work *work);
static K_WORK_DELAYABLE_DEFINE(repeat_work, repeat_step);

static void repeat_step(struct k_work *work)
{
	int dir = (int)atomic_get(&repeat_dir);

	ARG_UNUSED(work);
	if (dir) {
		ctrl_post(CTRL_REQ_CURSOR, dir);
		k_work_reschedule(&repeat_work, K_MSEC(REPEAT_PERIOD_MS));
	}
}

/* Key codes per button, as the board devicetree (or native_sim) gives them */
static const struct {
	uint16_t code;
	const char *name;
} buttons[BTN_COUNT] = {
	[BTN_ARM] = {INPUT_KEY_A, "ARM"},
	[BTN_FIRE] = {INPUT_KEY_SPACE, "FIRE"},
	[BTN_FILL] = {INPUT_KEY_F, "FILL"},
	[BTN_VENT] = {INPUT_KEY_V, "VENT"},
	[BTN_UP] = {INPUT_KEY_UP, "UP"},
	[BTN_DOWN] = {INPUT_KEY_DOWN, "DOWN"},
	[BTN_LEFT] = {INPUT_KEY_LEFT, "LEFT"},
	[BTN_RIGHT] = {INPUT_KEY_RIGHT, "RIGHT"},
	[BTN_OK] = {INPUT_KEY_ENTER, "OK"},
	[BTN_BACK] = {INPUT_KEY_BACK, "BACK"},
	[BTN_POWER] = {INPUT_KEY_POWER, "POWER"},
};

const char *button_name(enum button b)
{
	return b < BTN_COUNT ? buttons[b].name : "?";
}

/* Button test state, written from the input thread */
static struct k_spinlock diag_lock;
static struct inputs_diag diag;
static int64_t pressed_at[BTN_COUNT];

static int button_of(uint16_t code)
{
	for (int b = 0; b < BTN_COUNT; b++) {
		if (buttons[b].code == code) {
			return b;
		}
	}
	return -1;
}

static void record(int b, bool pressed)
{
	k_spinlock_key_t k = k_spin_lock(&diag_lock);
	int64_t now = k_uptime_get();
	struct button_event ev = {.button = b, .pressed = pressed, .time = now};

	if (pressed) {
		diag.pressed |= BIT(b);
		diag.count[b]++;
		pressed_at[b] = now;
	} else {
		diag.pressed &= ~BIT(b);
		ev.held_ms = (int32_t)(now - pressed_at[b]);
	}
	memmove(&diag.log[1], &diag.log[0], sizeof(diag.log[0]) * (INPUTS_LOG_LEN - 1));
	diag.log[0] = ev;
	diag.n_log = MIN(diag.n_log + 1, INPUTS_LOG_LEN);
	k_spin_unlock(&diag_lock, k);
}

void inputs_diag(struct inputs_diag *out)
{
	k_spinlock_key_t k = k_spin_lock(&diag_lock);

	*out = diag;
	k_spin_unlock(&diag_lock, k);
}

bool inputs_pressed(enum button b)
{
	k_spinlock_key_t k = k_spin_lock(&diag_lock);
	bool pressed = (diag.pressed & BIT(b)) != 0;

	k_spin_unlock(&diag_lock, k);
	return pressed;
}

void inputs_tap(enum button b, int n)
{
	for (int i = 0; i < n && b < BTN_COUNT; i++) {
		record(b, true);
		record(b, false);
	}
}

static void on_ok(bool pressed)
{
	if (pressed) {
		atomic_clear(&ok_long_fired);
		k_work_reschedule(&ok_long_work, K_MSEC(LONG_PRESS_MS));
	} else {
		/* Released before the long press fired: a normal select */
		k_work_cancel_delayable(&ok_long_work);
		if (!atomic_clear(&ok_long_fired)) {
			ctrl_post(CTRL_REQ_SELECT, 0);
		}
	}
}

static void on_input(struct input_event *evt, void *user_data)
{
	int b;

	ARG_UNUSED(user_data);

	/* Mouse wheel and click on native_sim, as the D-pad's up/down and OK */
	if (evt->type == INPUT_EV_REL && evt->code == INPUT_REL_WHEEL) {
		ctrl_post(CTRL_REQ_CURSOR, -evt->value);
		return;
	}
	if (evt->type != INPUT_EV_KEY) {
		return;
	}
	if (evt->code == INPUT_BTN_TOUCH) {
		on_ok(evt->value != 0);
		return;
	}

	b = button_of(evt->code);
	if (b < 0) {
		return;
	}
	record(b, evt->value != 0);

	switch (b) {
	case BTN_FIRE:
		atomic_set(&fire_held, evt->value != 0);
		break;
	case BTN_ARM:
		if (evt->value) {
			ctrl_post(CTRL_REQ_ARM, 0);
		}
		break;
	case BTN_BACK:
		/* On press, so that disarming never waits for a release */
		if (evt->value) {
			ctrl_post(CTRL_REQ_BACK, 0);
			k_work_reschedule(&back_long_work, K_MSEC(LONG_PRESS_MS));
		} else {
			k_work_cancel_delayable(&back_long_work);
		}
		break;
	case BTN_FILL:
		if (evt->value) {
			ctrl_post(CTRL_REQ_FILL, 0);
		}
		break;
	case BTN_VENT:
		if (evt->value) {
			ctrl_post(CTRL_REQ_VENT, 0);
		}
		break;
	case BTN_UP:
	case BTN_DOWN: {
		int dir = b == BTN_UP ? -1 : 1;

		if (evt->value) {
			ctrl_post(CTRL_REQ_CURSOR, dir);
			atomic_set(&repeat_dir, dir);
			k_work_reschedule(&repeat_work, K_MSEC(REPEAT_DELAY_MS));
		} else if (atomic_cas(&repeat_dir, dir, 0)) {
			k_work_cancel_delayable(&repeat_work);
		}
		break;
	}
	case BTN_LEFT:
	case BTN_RIGHT:
		if (evt->value) {
			ctrl_post(CTRL_REQ_ADJUST, b == BTN_LEFT ? -1 : 1);
		}
		break;
	case BTN_OK:
		on_ok(evt->value != 0);
		break;
	case BTN_POWER:
		if (evt->value) {
			ctrl_post(CTRL_REQ_POWER, 0);
		}
		break;
	default:
		break;
	}
}

/* All input devices: the buttons, and the mouse on native_sim */
INPUT_CALLBACK_DEFINE(NULL, on_input, NULL);

bool inputs_fire_held(void)
{
	return atomic_get(&fire_held) != 0;
}

void inputs_set_fire(bool held)
{
	atomic_set(&fire_held, held);
}
```

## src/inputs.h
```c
/*
 * Physical controls of the controller (keyboard keys on native_sim).
 * Momentary buttons (ARM, FILL, VENT, the D-pad, BACK, power) are posted
 * to the controller directly; the level inputs below are polled.
 */

#ifndef INPUTS_H_
#define INPUTS_H_

#include <stdbool.h>
#include <stdint.h>

bool inputs_fire_held(void);

/* Override for the shell, e.g. when the SDL window has no focus. */
void inputs_set_fire(bool held);

/* Every button, for the button test screen */
enum button {
	BTN_ARM,
	BTN_FIRE,
	BTN_FILL,
	BTN_VENT,
	BTN_UP,
	BTN_DOWN,
	BTN_LEFT,
	BTN_RIGHT,
	BTN_OK,
	BTN_BACK,
	BTN_POWER,
	BTN_COUNT,
};

const char *button_name(enum button b);

#define INPUTS_LOG_LEN 4

struct button_event {
	uint8_t button;
	bool pressed;
	int64_t time;      /* uptime, ms */
	int32_t held_ms;   /* on release: how long it was down */
};

struct inputs_diag {
	uint32_t pressed;               /* bit per enum button */
	uint32_t count[BTN_COUNT];      /* presses since boot */
	int n_log;                      /* entries in log, newest first */
	struct button_event log[INPUTS_LOG_LEN];
};

void inputs_diag(struct inputs_diag *out);

bool inputs_pressed(enum button b);

/*
 * Count n presses and releases of a button that never touched it: the
 * shell's stand-in for the D-pad, so that screens reading the counters
 * (the game, the button test) see the shell too. Acts on nothing else.
 */
void inputs_tap(enum button b, int n);

#endif /* INPUTS_H_ */
```
